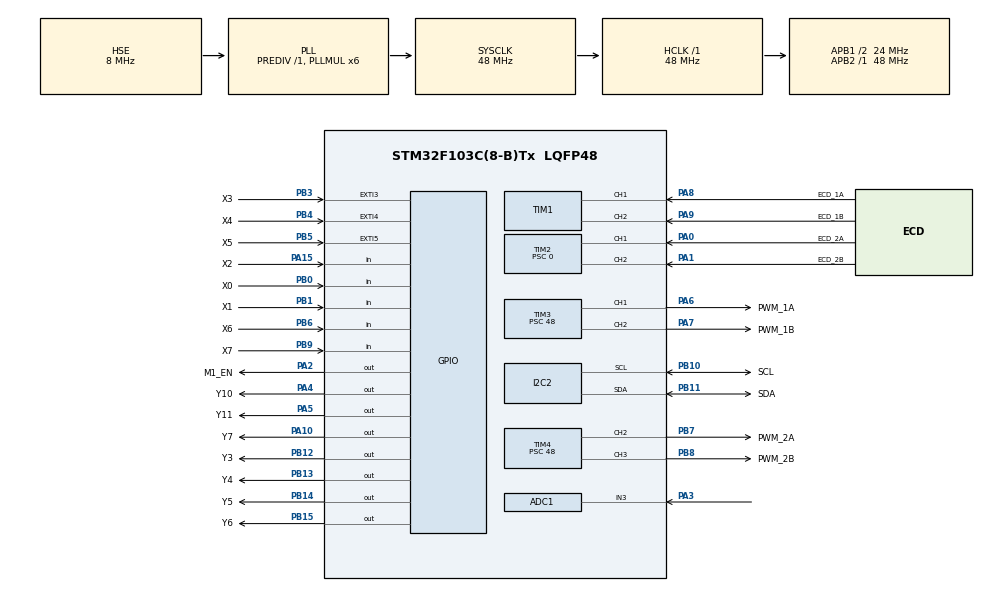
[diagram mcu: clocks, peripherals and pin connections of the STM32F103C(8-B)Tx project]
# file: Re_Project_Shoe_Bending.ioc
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ADC1.Channel-0\#ChannelRegularConversion=ADC_CHANNEL_3
ADC1.NbrOfConversionFlag=1
ADC1.Rank-0\#ChannelRegularConversion=1
ADC1.SamplingTime-0\#ChannelRegularConversion=ADC_SAMPLETIME_1CYCLE_5
ADC1.master=1
Mcu.Family=STM32F1
Mcu.Name=STM32F103C(8-B)Tx
Mcu.Package=LQFP48
NVIC.EXTI3_IRQn=true\:2\:0\:true\:true\:true\:1\:true\:true\:true
NVIC.EXTI4_IRQn=true\:2\:0\:true\:true\:true\:2\:true\:true\:true
NVIC.EXTI9_5_IRQn=true\:2\:0\:true\:true\:true\:3\:true\:true\:true
NVIC.PriorityGroup=NVIC_PRIORITYGROUP_4
NVIC.TIM4_IRQn=true\:1\:0\:true\:true\:true\:4\:true\:true\:true
PA0-WKUP.GPIO_Label=ECD_2A
PA0-WKUP.Signal=S_TIM2_CH1_ETR
PA1.GPIO_Label=ECD_2B
PA1.Signal=S_TIM2_CH2
PA10.GPIO_Label=Y7
PA10.GPIO_PuPd=GPIO_NOPULL
PA10.Signal=GPIO_Output
PA13.Mode=Serial_Wire
PA13.Signal=SYS_JTMS-SWDIO
PA14.Mode=Serial_Wire
PA14.Signal=SYS_JTCK-SWCLK
PA15.GPIO_Label=X2
PA15.GPIO_PuPd=GPIO_PULLUP
PA15.Signal=GPIO_Input
PA2.GPIO_Label=M1_EN
PA2.GPIO_PuPd=GPIO_NOPULL
PA2.Signal=GPIO_Output
PA3.Signal=ADCx_IN3
PA4.GPIO_Label=Y10
PA4.Signal=GPIO_Output
PA5.GPIO_Label=Y11
PA5.Signal=GPIO_Output
PA6.GPIO_Label=PWM_1A
PA6.Signal=S_TIM3_CH1
PA7.GPIO_Label=PWM_1B
PA7.Signal=S_TIM3_CH2
PA8.GPIO_Label=ECD_1A
PA8.Signal=S_TIM1_CH1
PA9.GPIO_Label=ECD_1B
PA9.Signal=S_TIM1_CH2
PB0.GPIO_Label=X0
PB0.GPIO_PuPd=GPIO_PULLUP
PB0.Signal=GPIO_Input
PB1.GPIO_Label=X1
PB1.GPIO_PuPd=GPIO_PULLUP
PB1.Signal=GPIO_Input
PB10.GPIO_Label=SCL
PB10.Mode=I2C
PB10.Signal=I2C2_SCL
PB11.GPIO_Label=SDA
PB11.Mode=I2C
PB11.Signal=I2C2_SDA
PB12.GPIO_Label=Y3
PB12.Signal=GPIO_Output
PB13.GPIO_Label=Y4
PB13.Signal=GPIO_Output
PB14.GPIO_Label=Y5
PB14.Signal=GPIO_Output
PB15.GPIO_Label=Y6
PB15.Signal=GPIO_Output
PB3.GPIO_Label=X3
PB3.GPIO_ModeDefaultEXTI=GPIO_MODE_IT_RISING_FALLING
PB3.GPIO_PuPd=GPIO_PULLUP
PB3.Signal=GPXTI3
PB4.GPIO_Label=X4
PB4.GPIO_ModeDefaultEXTI=GPIO_MODE_IT_RISING_FALLING
PB4.GPIO_PuPd=GPIO_PULLUP
PB4.Signal=GPXTI4
PB5.GPIO_Label=X5
PB5.GPIO_ModeDefaultEXTI=GPIO_MODE_IT_RISING_FALLING
PB5.GPIO_PuPd=GPIO_PULLUP
PB5.Signal=GPXTI5
PB6.GPIO_Label=X6
PB6.Signal=GPIO_Input
PB7.GPIO_Label=PWM_2A
PB7.Signal=S_TIM4_CH2
PB8.GPIO_Label=PWM_2B
PB8.Signal=S_TIM4_CH3
PB9.GPIO_Label=X7
PB9.GPIO_PuPd=GPIO_PULLUP
PB9.Signal=GPIO_Input
PD0-OSC_IN.GPIO_Label=OSC1
PD0-OSC_IN.Mode=HSE-External-Oscillator
PD0-OSC_IN.Signal=RCC_OSC_IN
PD1-OSC_OUT.GPIO_Label=OSC2
PD1-OSC_OUT.Mode=HSE-External-Oscillator
PD1-OSC_OUT.Signal=RCC_OSC_OUT
ProjectManager.HeapSize=0x200
ProjectManager.StackSize=0x400
ProjectManager.TargetToolchain=STM32CubeIDE
RCC.ADCPresc=RCC_ADCPCLK2_DIV4
RCC.AHBFreq_Value=48000000
RCC.APB1CLKDivider=RCC_HCLK_DIV2
RCC.APB1Freq_Value=24000000
RCC.APB1TimFreq_Value=48000000
RCC.APB2Freq_Value=48000000
RCC.APB2TimFreq_Value=48000000
RCC.HCLKFreq_Value=48000000
RCC.PLLMUL=RCC_PLL_MUL6
RCC.PLLSourceVirtual=RCC_PLLSOURCE_HSE
RCC.SYSCLKFreq_VALUE=48000000
RCC.SYSCLKSource=RCC_SYSCLKSOURCE_PLLCLK
RCC.USBFreq_Value=48000000
SH.ADCx_IN3.0=ADC1_IN3,IN3
SH.S_TIM1_CH1.0=TIM1_CH1,Encoder_Interface
SH.S_TIM1_CH2.0=TIM1_CH2,Encoder_Interface
SH.S_TIM2_CH1_ETR.0=TIM2_CH1,Encoder_Interface
SH.S_TIM2_CH2.0=TIM2_CH2,Encoder_Interface
SH.S_TIM3_CH1.0=TIM3_CH1,PWM Generation1 CH1
SH.S_TIM3_CH2.0=TIM3_CH2,PWM Generation2 CH2
SH.S_TIM4_CH2.0=TIM4_CH2,PWM Generation2 CH2
SH.S_TIM4_CH3.0=TIM4_CH3,PWM Generation3 CH3
TIM1.AutoReloadPreload=TIM_AUTORELOAD_PRELOAD_ENABLE
TIM1.EncoderMode=TIM_ENCODERMODE_TI12
TIM1.IC1Filter=10
TIM1.IC2Filter=10
TIM2.AutoReloadPreload=TIM_AUTORELOAD_PRELOAD_ENABLE
TIM2.EncoderMode=TIM_ENCODERMODE_TI12
TIM2.IC1Filter=10
TIM2.IC2Filter=10
TIM2.Period=65535
TIM2.Prescaler=0
TIM3.AutoReloadPreload=TIM_AUTORELOAD_PRELOAD_ENABLE
TIM3.Channel-PWM\ Generation1\ CH1=TIM_CHANNEL_1
TIM3.Channel-PWM\ Generation2\ CH2=TIM_CHANNEL_2
TIM3.Period=499
TIM3.Prescaler=48
TIM4.AutoReloadPreload=TIM_AUTORELOAD_PRELOAD_ENABLE
TIM4.Channel-PWM\ Generation2\ CH2=TIM_CHANNEL_2
TIM4.Channel-PWM\ Generation3\ CH3=TIM_CHANNEL_3
TIM4.Period=999
TIM4.Prescaler=48
board=custom

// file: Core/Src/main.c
/* USER CODE BEGIN Header */
/**
 ******************************************************************************
 * @file           : main.c
 * @brief          : Main program body
 ******************************************************************************
 * @attention
 *
 * Copyright (c) 2022 STMicroelectronics.
 * All rights reserved.
 *
 * This software is licensed under terms that can be found in the LICENSE file
 * in the root directory of this software component.
 * If no LICENSE file comes with this software, it is provided AS-IS.
 *
 ******************************************************************************
 */
/* USER CODE END Header */
#include "main.h"

/* USER CODE BEGIN Includes */
//#include "test_handler.h"
#include "user_code/UserCode.h"
/* USER CODE END Includes */

ADC_HandleTypeDef hadc1;

I2C_HandleTypeDef hi2c2;

TIM_HandleTypeDef htim1;
TIM_HandleTypeDef htim2;
TIM_HandleTypeDef htim3;
TIM_HandleTypeDef htim4;

void SystemClock_Config(void);
static void MX_GPIO_Init(void);
static void MX_TIM1_Init(void);
static void MX_TIM2_Init(void);
static void MX_TIM3_Init(void);
static void MX_TIM4_Init(void);
static void MX_I2C2_Init(void);
static void MX_ADC1_Init(void);
static void MX_NVIC_Init(void);

int main(void)
{

  /* MCU Configuration--------------------------------------------------------*/

  /* Reset of all peripherals, Initializes the Flash interface and the Systick. */
  HAL_Init();

  /* Configure the system clock */
  SystemClock_Config();

  /* Initialize all configured peripherals */
  MX_GPIO_Init();
  MX_TIM1_Init();
  MX_TIM2_Init();
  MX_TIM3_Init();
  MX_TIM4_Init();
  MX_I2C2_Init();
  MX_ADC1_Init();

  /* Initialize interrupts */
  MX_NVIC_Init();
  /* USER CODE BEGIN 2 */
  start_up();
  /* USER CODE END 2 */

  /* Infinite loop */
  while (1) {

    /* USER CODE BEGIN 3 */
	main_loop();
  }
  /*===============================================================================*/

  /* USER CODE END 3 */
}

void SystemClock_Config(void)
{
  RCC_OscInitTypeDef RCC_OscInitStruct = {0};
  RCC_ClkInitTypeDef RCC_ClkInitStruct = {0};
  RCC_PeriphCLKInitTypeDef PeriphClkInit = {0};

  /** Initializes the RCC Oscillators according to the specified parameters
  * in the RCC_OscInitTypeDef structure.
  */
  RCC_OscInitStruct.OscillatorType = RCC_OSCILLATORTYPE_HSE;
  RCC_OscInitStruct.HSEState = RCC_HSE_ON;
  RCC_OscInitStruct.HSEPredivValue = RCC_HSE_PREDIV_DIV1;
  RCC_OscInitStruct.HSIState = RCC_HSI_ON;
  RCC_OscInitStruct.PLL.PLLState = RCC_PLL_ON;
  RCC_OscInitStruct.PLL.PLLSource = RCC_PLLSOURCE_HSE;
  RCC_OscInitStruct.PLL.PLLMUL = RCC_PLL_MUL6;
  if (HAL_RCC_OscConfig(&RCC_OscInitStruct) != HAL_OK)
  {
    Error_Handler();
  }

  /** Initializes the CPU, AHB and APB buses clocks
  */
  RCC_ClkInitStruct.ClockType = RCC_CLOCKTYPE_HCLK|RCC_CLOCKTYPE_SYSCLK
                              |RCC_CLOCKTYPE_PCLK1|RCC_CLOCKTYPE_PCLK2;
  RCC_ClkInitStruct.SYSCLKSource = RCC_SYSCLKSOURCE_PLLCLK;
  RCC_ClkInitStruct.AHBCLKDivider = RCC_SYSCLK_DIV1;
  RCC_ClkInitStruct.APB1CLKDivider = RCC_HCLK_DIV2;
  RCC_ClkInitStruct.APB2CLKDivider = RCC_HCLK_DIV1;

  if (HAL_RCC_ClockConfig(&RCC_ClkInitStruct, FLASH_LATENCY_1) != HAL_OK)
  {
    Error_Handler();
  }
  PeriphClkInit.PeriphClockSelection = RCC_PERIPHCLK_ADC;
  PeriphClkInit.AdcClockSelection = RCC_ADCPCLK2_DIV4;
  if (HAL_RCCEx_PeriphCLKConfig(&PeriphClkInit) != HAL_OK)
  {
    Error_Handler();
  }
}

/**
  * @brief NVIC Configuration.
  * @retval None
  */
static void MX_NVIC_Init(void)
{
  /* EXTI3_IRQn interrupt configuration */
  HAL_NVIC_SetPriority(EXTI3_IRQn, 2, 0);
  HAL_NVIC_EnableIRQ(EXTI3_IRQn);
  /* EXTI4_IRQn interrupt configuration */
  HAL_NVIC_SetPriority(EXTI4_IRQn, 2, 0);
  HAL_NVIC_EnableIRQ(EXTI4_IRQn);
  /* EXTI9_5_IRQn interrupt configuration */
  HAL_NVIC_SetPriority(EXTI9_5_IRQn, 2, 0);
  HAL_NVIC_EnableIRQ(EXTI9_5_IRQn);
  /* TIM4_IRQn interrupt configuration */
  HAL_NVIC_SetPriority(TIM4_IRQn, 1, 0);
  HAL_NVIC_EnableIRQ(TIM4_IRQn);
}

static void MX_ADC1_Init(void)
{

  ADC_ChannelConfTypeDef sConfig = {0};

  /** Common config
  */
  hadc1.Instance = ADC1;
  hadc1.Init.ScanConvMode = ADC_SCAN_DISABLE;
  hadc1.Init.ContinuousConvMode = DISABLE;
  hadc1.Init.DiscontinuousConvMode = DISABLE;
  hadc1.Init.ExternalTrigConv = ADC_SOFTWARE_START;
  hadc1.Init.DataAlign = ADC_DATAALIGN_RIGHT;
  hadc1.Init.NbrOfConversion = 1;
  if (HAL_ADC_Init(&hadc1) != HAL_OK)
  {
    Error_Handler();
  }

  /** Configure Regular Channel
  */
  sConfig.Channel = ADC_CHANNEL_3;
  sConfig.Rank = ADC_REGULAR_RANK_1;
  sConfig.SamplingTime = ADC_SAMPLETIME_1CYCLE_5;
  if (HAL_ADC_ConfigChannel(&hadc1, &sConfig) != HAL_OK)
  {
    Error_Handler();
  }

}

static void MX_I2C2_Init(void)
{

  hi2c2.Instance = I2C2;
  hi2c2.Init.ClockSpeed = 100000;
  hi2c2.Init.DutyCycle = I2C_DUTYCYCLE_2;
  hi2c2.Init.OwnAddress1 = 0;
  hi2c2.Init.AddressingMode = I2C_ADDRESSINGMODE_7BIT;
  hi2c2.Init.DualAddressMode = I2C_DUALADDRESS_DISABLE;
  hi2c2.Init.OwnAddress2 = 0;
  hi2c2.Init.GeneralCallMode = I2C_GENERALCALL_DISABLE;
  hi2c2.Init.NoStretchMode = I2C_NOSTRETCH_DISABLE;
  if (HAL_I2C_Init(&hi2c2) != HAL_OK)
  {
    Error_Handler();
  }

}

static void MX_TIM1_Init(void)
{

  TIM_Encoder_InitTypeDef sConfig = {0};
  TIM_MasterConfigTypeDef sMasterConfig = {0};

  htim1.Instance = TIM1;
  htim1.Init.Prescaler = 0;
  htim1.Init.CounterMode = TIM_COUNTERMODE_UP;
  htim1.Init.Period = 65535;
  htim1.Init.ClockDivision = TIM_CLOCKDIVISION_DIV1;
  htim1.Init.RepetitionCounter = 0;
  htim1.Init.AutoReloadPreload = TIM_AUTORELOAD_PRELOAD_ENABLE;
  sConfig.EncoderMode = TIM_ENCODERMODE_TI12;
  sConfig.IC1Polarity = TIM_ICPOLARITY_RISING;
  sConfig.IC1Selection = TIM_ICSELECTION_DIRECTTI;
  sConfig.IC1Prescaler = TIM_ICPSC_DIV1;
  sConfig.IC1Filter = 10;
  sConfig.IC2Polarity = TIM_ICPOLARITY_RISING;
  sConfig.IC2Selection = TIM_ICSELECTION_DIRECTTI;
  sConfig.IC2Prescaler = TIM_ICPSC_DIV1;
  sConfig.IC2Filter = 10;
  if (HAL_TIM_Encoder_Init(&htim1, &sConfig) != HAL_OK)
  {
    Error_Handler();
  }
  sMasterConfig.MasterOutputTrigger = TIM_TRGO_RESET;
  sMasterConfig.MasterSlaveMode = TIM_MASTERSLAVEMODE_DISABLE;
  if (HAL_TIMEx_MasterConfigSynchronization(&htim1, &sMasterConfig) != HAL_OK)
  {
    Error_Handler();
  }

}

static void MX_TIM2_Init(void)
{

  TIM_Encoder_InitTypeDef sConfig = {0};
  TIM_MasterConfigTypeDef sMasterConfig = {0};

  htim2.Instance = TIM2;
  htim2.Init.Prescaler = 0;
  htim2.Init.CounterMode = TIM_COUNTERMODE_UP;
  htim2.Init.Period = 65535;
  htim2.Init.ClockDivision = TIM_CLOCKDIVISION_DIV1;
  htim2.Init.AutoReloadPreload = TIM_AUTORELOAD_PRELOAD_ENABLE;
  sConfig.EncoderMode = TIM_ENCODERMODE_TI12;
  sConfig.IC1Polarity = TIM_ICPOLARITY_RISING;
  sConfig.IC1Selection = TIM_ICSELECTION_DIRECTTI;
  sConfig.IC1Prescaler = TIM_ICPSC_DIV1;
  sConfig.IC1Filter = 10;
  sConfig.IC2Polarity = TIM_ICPOLARITY_RISING;
  sConfig.IC2Selection = TIM_ICSELECTION_DIRECTTI;
  sConfig.IC2Prescaler = TIM_ICPSC_DIV1;
  sConfig.IC2Filter = 10;
  if (HAL_TIM_Encoder_Init(&htim2, &sConfig) != HAL_OK)
  {
    Error_Handler();
  }
  sMasterConfig.MasterOutputTrigger = TIM_TRGO_RESET;
  sMasterConfig.MasterSlaveMode = TIM_MASTERSLAVEMODE_DISABLE;
  if (HAL_TIMEx_MasterConfigSynchronization(&htim2, &sMasterConfig) != HAL_OK)
  {
    Error_Handler();
  }

}

static void MX_TIM3_Init(void)
{

  TIM_MasterConfigTypeDef sMasterConfig = {0};
  TIM_OC_InitTypeDef sConfigOC = {0};

  htim3.Instance = TIM3;
  htim3.Init.Prescaler = 48;
  htim3.Init.CounterMode = TIM_COUNTERMODE_UP;
  htim3.Init.Period = 499;
  htim3.Init.ClockDivision = TIM_CLOCKDIVISION_DIV1;
  htim3.Init.AutoReloadPreload = TIM_AUTORELOAD_PRELOAD_ENABLE;
  if (HAL_TIM_PWM_Init(&htim3) != HAL_OK)
  {
    Error_Handler();
  }
  sMasterConfig.MasterOutputTrigger = TIM_TRGO_RESET;
  sMasterConfig.MasterSlaveMode = TIM_MASTERSLAVEMODE_DISABLE;
  if (HAL_TIMEx_MasterConfigSynchronization(&htim3, &sMasterConfig) != HAL_OK)
  {
    Error_Handler();
  }
  sConfigOC.OCMode = TIM_OCMODE_PWM1;
  sConfigOC.Pulse = 0;
  sConfigOC.OCPolarity = TIM_OCPOLARITY_HIGH;
  sConfigOC.OCFastMode = TIM_OCFAST_DISABLE;
  if (HAL_TIM_PWM_ConfigChannel(&htim3, &sConfigOC, TIM_CHANNEL_1) != HAL_OK)
  {
    Error_Handler();
  }
  if (HAL_TIM_PWM_ConfigChannel(&htim3, &sConfigOC, TIM_CHANNEL_2) != HAL_OK)
  {
    Error_Handler();
  }
  HAL_TIM_MspPostInit(&htim3);

}

static void MX_TIM4_Init(void)
{

  TIM_MasterConfigTypeDef sMasterConfig = {0};
  TIM_OC_InitTypeDef sConfigOC = {0};

  htim4.Instance = TIM4;
  htim4.Init.Prescaler = 48;
  htim4.Init.CounterMode = TIM_COUNTERMODE_UP;
  htim4.Init.Period = 999;
  htim4.Init.ClockDivision = TIM_CLOCKDIVISION_DIV1;
  htim4.Init.AutoReloadPreload = TIM_AUTORELOAD_PRELOAD_ENABLE;
  if (HAL_TIM_PWM_Init(&htim4) != HAL_OK)
  {
    Error_Handler();
  }
  sMasterConfig.MasterOutputTrigger = TIM_TRGO_RESET;
  sMasterConfig.MasterSlaveMode = TIM_MASTERSLAVEMODE_DISABLE;
  if (HAL_TIMEx_MasterConfigSynchronization(&htim4, &sMasterConfig) != HAL_OK)
  {
    Error_Handler();
  }
  sConfigOC.OCMode = TIM_OCMODE_PWM1;
  sConfigOC.Pulse = 0;
  sConfigOC.OCPolarity = TIM_OCPOLARITY_HIGH;
  sConfigOC.OCFastMode = TIM_OCFAST_DISABLE;
  if (HAL_TIM_PWM_ConfigChannel(&htim4, &sConfigOC, TIM_CHANNEL_2) != HAL_OK)
  {
    Error_Handler();
  }
  if (HAL_TIM_PWM_ConfigChannel(&htim4, &sConfigOC, TIM_CHANNEL_3) != HAL_OK)
  {
    Error_Handler();
  }
  HAL_TIM_MspPostInit(&htim4);

}

static void MX_GPIO_Init(void)
{
  GPIO_InitTypeDef GPIO_InitStruct = {0};

  /* GPIO Ports Clock Enable */
  __HAL_RCC_GPIOD_CLK_ENABLE();
  __HAL_RCC_GPIOA_CLK_ENABLE();
  __HAL_RCC_GPIOB_CLK_ENABLE();

  /*Configure GPIO pin Output Level */
  HAL_GPIO_WritePin(GPIOA, M1_EN_Pin|Y10_Pin|Y11_Pin|Y7_Pin, GPIO_PIN_RESET);

  /*Configure GPIO pin Output Level */
  HAL_GPIO_WritePin(GPIOB, Y3_Pin|Y4_Pin|Y5_Pin|Y6_Pin, GPIO_PIN_RESET);

  /*Configure GPIO pins : M1_EN_Pin Y10_Pin Y11_Pin Y7_Pin */
  GPIO_InitStruct.Pin = M1_EN_Pin|Y10_Pin|Y11_Pin|Y7_Pin;
  GPIO_InitStruct.Mode = GPIO_MODE_OUTPUT_PP;
  GPIO_InitStruct.Pull = GPIO_NOPULL;
  GPIO_InitStruct.Speed = GPIO_SPEED_FREQ_LOW;
  HAL_GPIO_Init(GPIOA, &GPIO_InitStruct);

  /*Configure GPIO pins : X0_Pin X1_Pin X7_Pin */
  GPIO_InitStruct.Pin = X0_Pin|X1_Pin|X7_Pin;
  GPIO_InitStruct.Mode = GPIO_MODE_INPUT;
  GPIO_InitStruct.Pull = GPIO_PULLUP;
  HAL_GPIO_Init(GPIOB, &GPIO_InitStruct);

  /*Configure GPIO pin : PB2 */
  GPIO_InitStruct.Pin = GPIO_PIN_2;
  GPIO_InitStruct.Mode = GPIO_MODE_ANALOG;
  HAL_GPIO_Init(GPIOB, &GPIO_InitStruct);

  /*Configure GPIO pins : Y3_Pin Y4_Pin Y5_Pin Y6_Pin */
  GPIO_InitStruct.Pin = Y3_Pin|Y4_Pin|Y5_Pin|Y6_Pin;
  GPIO_InitStruct.Mode = GPIO_MODE_OUTPUT_PP;
  GPIO_InitStruct.Pull = GPIO_NOPULL;
  GPIO_InitStruct.Speed = GPIO_SPEED_FREQ_LOW;
  HAL_GPIO_Init(GPIOB, &GPIO_InitStruct);

  /*Configure GPIO pins : PA11 PA12 */
  GPIO_InitStruct.Pin = GPIO_PIN_11|GPIO_PIN_12;
  GPIO_InitStruct.Mode = GPIO_MODE_ANALOG;
  HAL_GPIO_Init(GPIOA, &GPIO_InitStruct);

  /*Configure GPIO pin : X2_Pin */
  GPIO_InitStruct.Pin = X2_Pin;
  GPIO_InitStruct.Mode = GPIO_MODE_INPUT;
  GPIO_InitStruct.Pull = GPIO_PULLUP;
  HAL_GPIO_Init(X2_GPIO_Port, &GPIO_InitStruct);

  /*Configure GPIO pins : X3_Pin X4_Pin X5_Pin */
  GPIO_InitStruct.Pin = X3_Pin|X4_Pin|X5_Pin;
  GPIO_InitStruct.Mode = GPIO_MODE_IT_RISING_FALLING;
  GPIO_InitStruct.Pull = GPIO_PULLUP;
  HAL_GPIO_Init(GPIOB, &GPIO_InitStruct);

  /*Configure GPIO pin : X6_Pin */
  GPIO_InitStruct.Pin = X6_Pin;
  GPIO_InitStruct.Mode = GPIO_MODE_INPUT;
  GPIO_InitStruct.Pull = GPIO_NOPULL;
  HAL_GPIO_Init(X6_GPIO_Port, &GPIO_InitStruct);

}

void Error_Handler(void)
{
  __disable_irq();
  while (1) {
  }
}
